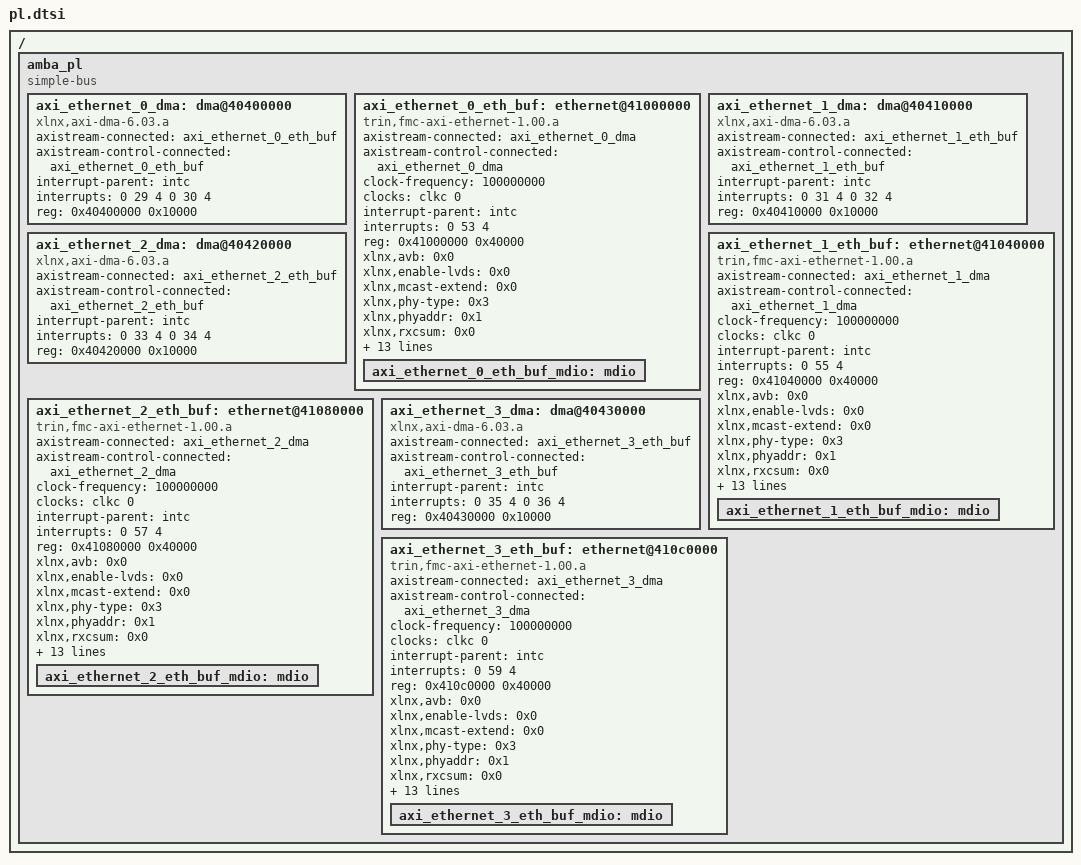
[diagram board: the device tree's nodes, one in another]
/*
 * CAUTION: This file is automatically generated by Xilinx.
 * Version:  
 * Today is: Tue Apr 21 10:52:31 2015
*/


/ {
	amba_pl: amba_pl {
		#address-cells = <1>;
		#size-cells = <1>;
		compatible = "simple-bus";
		ranges ;
		axi_ethernet_0_dma: dma@40400000 {
			axistream-connected = <&axi_ethernet_0_eth_buf>;
			axistream-control-connected = <&axi_ethernet_0_eth_buf>;
			compatible = "xlnx,axi-dma-6.03.a", "xlnx,axi-dma-1.00.a";
			interrupt-parent = <&intc>;
			interrupts = <0 29 4 0 30 4>;
			reg = <0x40400000 0x10000>;
		};
		axi_ethernet_0_eth_buf: ethernet@41000000 {
			axistream-connected = <&axi_ethernet_0_dma>;
			axistream-control-connected = <&axi_ethernet_0_dma>;
			clock-frequency = <100000000>;
			clock-names = "ref_clk";
			clocks = <&clkc 0>;
			compatible = "trin,fmc-axi-ethernet-1.00.a";
			device_type = "network";
			interrupt-parent = <&intc>;
			interrupts = <0 53 4>;
			reg = <0x41000000 0x40000>;
			xlnx,avb = <0x0>;
			xlnx,enable-lvds = <0x0>;
			xlnx,mcast-extend = <0x0>;
			xlnx,phy-type = <0x3>;
			xlnx,phyaddr = <0x1>;
			xlnx,rxcsum = <0x0>;
			xlnx,rxmem = <0x1000>;
			xlnx,rxvlan-strp = <0x0>;
			xlnx,rxvlan-tag = <0x0>;
			xlnx,rxvlan-tran = <0x0>;
			xlnx,simulation = <0x0>;
			xlnx,stats = <0x1>;
			xlnx,temac-addr-width = <0xc>;
			xlnx,txcsum = <0x0>;
			xlnx,txmem = <0x1000>;
			xlnx,txvlan-strp = <0x0>;
			xlnx,txvlan-tag = <0x0>;
			xlnx,txvlan-tran = <0x0>;
			xlnx,type = <0x1>;
			axi_ethernet_0_eth_buf_mdio: mdio {
				#address-cells = <1>;
				#size-cells = <0>;
			};
		};
		axi_ethernet_1_dma: dma@40410000 {
			axistream-connected = <&axi_ethernet_1_eth_buf>;
			axistream-control-connected = <&axi_ethernet_1_eth_buf>;
			compatible = "xlnx,axi-dma-6.03.a", "xlnx,axi-dma-1.00.a";
			interrupt-parent = <&intc>;
			interrupts = <0 31 4 0 32 4>;
			reg = <0x40410000 0x10000>;
		};
		axi_ethernet_1_eth_buf: ethernet@41040000 {
			axistream-connected = <&axi_ethernet_1_dma>;
			axistream-control-connected = <&axi_ethernet_1_dma>;
			clock-frequency = <100000000>;
			clock-names = "ref_clk";
			clocks = <&clkc 0>;
			compatible = "trin,fmc-axi-ethernet-1.00.a";
			device_type = "network";
			interrupt-parent = <&intc>;
			interrupts = <0 55 4>;
			reg = <0x41040000 0x40000>;
			xlnx,avb = <0x0>;
			xlnx,enable-lvds = <0x0>;
			xlnx,mcast-extend = <0x0>;
			xlnx,phy-type = <0x3>;
			xlnx,phyaddr = <0x1>;
			xlnx,rxcsum = <0x0>;
			xlnx,rxmem = <0x1000>;
			xlnx,rxvlan-strp = <0x0>;
			xlnx,rxvlan-tag = <0x0>;
			xlnx,rxvlan-tran = <0x0>;
			xlnx,simulation = <0x0>;
			xlnx,stats = <0x1>;
			xlnx,temac-addr-width = <0xc>;
			xlnx,txcsum = <0x0>;
			xlnx,txmem = <0x1000>;
			xlnx,txvlan-strp = <0x0>;
			xlnx,txvlan-tag = <0x0>;
			xlnx,txvlan-tran = <0x0>;
			xlnx,type = <0x1>;
			axi_ethernet_1_eth_buf_mdio: mdio {
				#address-cells = <1>;
				#size-cells = <0>;
			};
		};
		axi_ethernet_2_dma: dma@40420000 {
			axistream-connected = <&axi_ethernet_2_eth_buf>;
			axistream-control-connected = <&axi_ethernet_2_eth_buf>;
			compatible = "xlnx,axi-dma-6.03.a", "xlnx,axi-dma-1.00.a";
			interrupt-parent = <&intc>;
			interrupts = <0 33 4 0 34 4>;
			reg = <0x40420000 0x10000>;
		};
		axi_ethernet_2_eth_buf: ethernet@41080000 {
			axistream-connected = <&axi_ethernet_2_dma>;
			axistream-control-connected = <&axi_ethernet_2_dma>;
			clock-frequency = <100000000>;
			clock-names = "ref_clk";
			clocks = <&clkc 0>;
			compatible = "trin,fmc-axi-ethernet-1.00.a";
			device_type = "network";
			interrupt-parent = <&intc>;
			interrupts = <0 57 4>;
			reg = <0x41080000 0x40000>;
			xlnx,avb = <0x0>;
			xlnx,enable-lvds = <0x0>;
			xlnx,mcast-extend = <0x0>;
			xlnx,phy-type = <0x3>;
			xlnx,phyaddr = <0x1>;
			xlnx,rxcsum = <0x0>;
			xlnx,rxmem = <0x1000>;
			xlnx,rxvlan-strp = <0x0>;
			xlnx,rxvlan-tag = <0x0>;
			xlnx,rxvlan-tran = <0x0>;
			xlnx,simulation = <0x0>;
			xlnx,stats = <0x1>;
			xlnx,temac-addr-width = <0xc>;
			xlnx,txcsum = <0x0>;
			xlnx,txmem = <0x1000>;
			xlnx,txvlan-strp = <0x0>;
			xlnx,txvlan-tag = <0x0>;
			xlnx,txvlan-tran = <0x0>;
			xlnx,type = <0x1>;
			axi_ethernet_2_eth_buf_mdio: mdio {
				#address-cells = <1>;
				#size-cells = <0>;
			};
		};
		axi_ethernet_3_dma: dma@40430000 {
			axistream-connected = <&axi_ethernet_3_eth_buf>;
			axistream-control-connected = <&axi_ethernet_3_eth_buf>;
			compatible = "xlnx,axi-dma-6.03.a", "xlnx,axi-dma-1.00.a";
			interrupt-parent = <&intc>;
			interrupts = <0 35 4 0 36 4>;
			reg = <0x40430000 0x10000>;
		};
		axi_ethernet_3_eth_buf: ethernet@410c0000 {
			axistream-connected = <&axi_ethernet_3_dma>;
			axistream-control-connected = <&axi_ethernet_3_dma>;
			clock-frequency = <100000000>;
			clock-names = "ref_clk";
			clocks = <&clkc 0>;
			compatible = "trin,fmc-axi-ethernet-1.00.a";
			device_type = "network";
			interrupt-parent = <&intc>;
			interrupts = <0 59 4>;
			reg = <0x410c0000 0x40000>;
			xlnx,avb = <0x0>;
			xlnx,enable-lvds = <0x0>;
			xlnx,mcast-extend = <0x0>;
			xlnx,phy-type = <0x3>;
			xlnx,phyaddr = <0x1>;
			xlnx,rxcsum = <0x0>;
			xlnx,rxmem = <0x1000>;
			xlnx,rxvlan-strp = <0x0>;
			xlnx,rxvlan-tag = <0x0>;
			xlnx,rxvlan-tran = <0x0>;
			xlnx,simulation = <0x0>;
			xlnx,stats = <0x1>;
			xlnx,temac-addr-width = <0xc>;
			xlnx,txcsum = <0x0>;
			xlnx,txmem = <0x1000>;
			xlnx,txvlan-strp = <0x0>;
			xlnx,txvlan-tag = <0x0>;
			xlnx,txvlan-tran = <0x0>;
			xlnx,type = <0x1>;
			axi_ethernet_3_eth_buf_mdio: mdio {
				#address-cells = <1>;
				#size-cells = <0>;
			};
		};
	};
};
